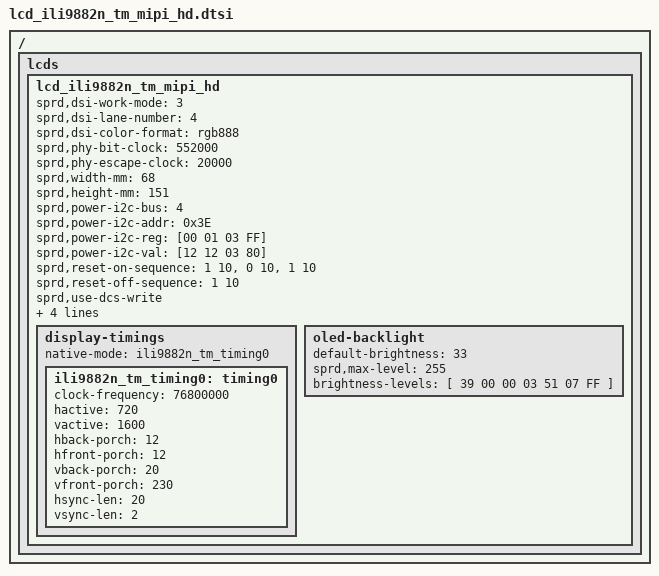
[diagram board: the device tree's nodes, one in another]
/*
 * ili9882n tm HD Scaling-Up LCD config dtsi file for spreadtrum
 *
 * Copyright (C) 2018, Spreadtrum Communications Inc.
 *
 * SPDX-License-Identifier: (GPL-2.0+ OR MIT)
 */

/ {
	fragment {
		target-path = "/";
		__overlay__ {
			lcds {
				lcd_ili9882n_tm_mipi_hd: lcd_ili9882n_tm_mipi_hd {

					sprd,dsi-work-mode = <3>; /* video burst mode*/
					sprd,dsi-lane-number = <4>;
					sprd,dsi-color-format = "rgb888";

					sprd,phy-bit-clock = <552000>;	/* kbps */    
					sprd,phy-escape-clock = <20000>;/* kHz */  

					sprd,width-mm = <68>;
					sprd,height-mm = <151>;

					//sprd,esd-check-mode = <0>;
					//sprd,esd-check-period = <2000>;
					//sprd,esd-check-regs = <0xA>;
					//sprd,esd-return-code = <0x9c>;

					sprd,power-i2c-bus = <4>;
        			sprd,power-i2c-addr = <0x3E>;
        			/*sprd,power-i2c-speed = <400000>;*/
        			sprd,power-i2c-reg = [00 01 03 FF];
        			sprd,power-i2c-val = [12 12 03 80];

					sprd,reset-on-sequence = <1 10>, <0 10>, <1 10>;
					sprd,reset-off-sequence = <1 10>;

					sprd,use-dcs-write;

					sprd,initial-command = [
						39 00 00 04 FF 98 82 00
						39 00 00 03 51 07 FF
						15 00 00 02 53 2C
						15 00 00 02 55 01
						05 78 00 01 11
						05 14 00 01 29
						];

					sprd,sleep-in-command = [
						05 32 00 01 28
						05 96 00 01 10
						];

					display-timings {
						native-mode = <&ili9882n_tm_timing0>;

						ili9882n_tm_timing0: timing0 {
							clock-frequency = <76800000>;       
							hactive = <720>;
							vactive = <1600>;
							hback-porch = <12>;
							hfront-porch = <12>;
							vback-porch = <20>;
							vfront-porch = <230>;
							hsync-len = <20>;
							vsync-len = <2>;
						};
					};
			
					oled-backlight {			
						default-brightness = <33>;	
						sprd,max-level = <255>;
						brightness-levels = [				
            		    	39 00 00 03 51 07 FF
						];
					};
				};
			};
		};
	};
};
